# MK65F18 register map
Vendor: NXP Semiconductors; Series: Kinetis_K; File version: 1.6
CPU: CM4 r0p1, little endian, no MPU, FPU, VTOR, 4 interrupt priority bits
Registers are 32-bit, read-write, reset 0x0 unless marked. A register's access mark holds for its fields unless they carry their own. Offsets are from the block's base; [hi:lo] are bit positions; {n}, {i} and the like mark numbered series; 'fields as' and 'values as' point back to an identical list.

## RFSYS — System register file
Base 0x40041000; register names take the prefix RFSYS_
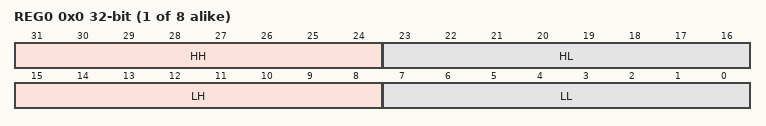
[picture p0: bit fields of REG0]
{0x0+4i} REG{i} (i=0..7) — Register file register
  [31:24] HH — High higher byte
  [23:16] HL — High lower byte
  [15:8] LH — Low higher byte
  [7:0] LL — Low lower byte

## TSI0 — Touch sense input
Base 0x40045000; register names take the prefix TSI0_
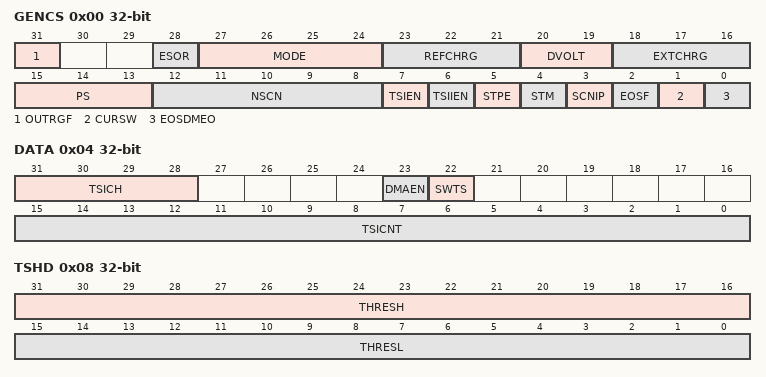
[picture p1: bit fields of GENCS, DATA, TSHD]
0x00 GENCS — TSI General Control and Status Register
  [31] OUTRGF — Out of Range Flag.
  [28] ESOR — End-of-scan or Out-of-Range Interrupt Selection
    0=Out-of-range interrupt is allowed; 1=End-of-scan interrupt is allowed
  [27:24] MODE — TSI analog modes setup and status bits.
    0=Set TSI in capacitive sensing(non-noise detection) mode; 4=Set TSI analog to work in single threshold noise detection mode and the frequency limitation circuit is disabled; 8=Set TSI analog to work in single threshold noise detection mode and the frequency limitation circuit is enabled to work in higher frequencies operations; 12=Set TSI analog to work in automatic noise detection mode
  [23:21] REFCHRG
    0=500 nA; 1=1 uA; 2=2 uA; 3=4 uA; 4=8 uA; 5=16 uA; 6=32 uA; 7=64 uA
  [20:19] DVOLT
    0=DV = 1.026 V; VP = 1.328 V; Vm = 0.302 V; 1=DV = 0.592 V; VP = 1.111 V; Vm = 0.519 V; 2=DV = 0.342 V; VP = 0.986 V; Vm = 0.644 V; 3=DV = 0.197 V; VP = 0.914 V; Vm = 0.716 V
  [18:16] EXTCHRG
    values as REFCHRG
  [15:13] PS
    0=Electrode Oscillator Frequency divided by 1; 1=Electrode Oscillator Frequency divided by 2; 2=Electrode Oscillator Frequency divided by 4; 3=Electrode Oscillator Frequency divided by 8; 4=Electrode Oscillator Frequency divided by 16; 5=Electrode Oscillator Frequency divided by 32; 6=Electrode Oscillator Frequency divided by 64; 7=Electrode Oscillator Frequency divided by 128
  [12:8] NSCN
    0=Once per electrode; 1=Twice per electrode; {v}={v+1} times per electrode (v=2..31)
  [7] TSIEN — Touch Sensing Input Module Enable
    0=TSI module disabled; 1=TSI module enabled
  [6] TSIIEN — Touch Sensing Input Interrupt Enable
    0=TSI interrupt is disabled; 1=TSI interrupt is enabled
  [5] STPE — TSI STOP Enable
    0=TSI is disabled when MCU goes into low power mode; 1=Allows TSI to continue running in all low power modes
  [4] STM — Scan Trigger Mode
    0=Software trigger scan; 1=Hardware trigger scan
  [3] SCNIP ro — Scan In Progress Status
    0=No scan in progress; 1=Scan in progress
  [2] EOSF — End of Scan Flag
    0=Scan not complete; 1=Scan complete
  [1] CURSW
    0=The current source pair are not swapped; 1=The current source pair are swapped
  [0] EOSDMEO — End-of-Scan DMA Transfer Request Enable Only
    0=Do not enable the End-of-Scan DMA transfer request only. Depending on ESOR state, either Out-of-Range or End-of-Scan can trigger a DMA transfer request and interrupt.; 1=Only the End-of-Scan event can trigger a DMA transfer request. The Out-of-Range event only and always triggers an interrupt if TSIIE is set.
0x04 DATA — TSI DATA Register
  [31:28] TSICH
    {v}=Channel {v} (v=0..15)
  [23] DMAEN — DMA Transfer Enabled
    0=Interrupt is selected when the interrupt enable bit is set and the corresponding TSI events assert; 1=DMA transfer request is selected when the interrupt enable bit is set and the corresponding TSI events assert
  [22] SWTS wo — Software Trigger Start
    0=No effect; 1=Start a scan to determine which channel is specified by TSI_DATA[TSICH]
  [15:0] TSICNT ro — TSI Conversion Counter Value
0x08 TSHD — TSI Threshold Register
  [31:16] THRESH — TSI Wakeup Channel High-threshold
  [15:0] THRESL — TSI Wakeup Channel Low-threshold

## EWM — External Watchdog Monitor
Base 0x40061000; register names take the prefix EWM_
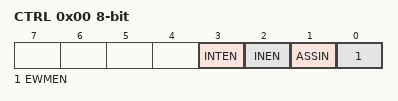
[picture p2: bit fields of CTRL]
0x00 CTRL 8-bit — Control Register
  [3] INTEN — Interrupt Enable.
  [2] INEN — Input Enable.
  [1] ASSIN — EWM_in's Assertion State Select.
  [0] EWMEN — EWM enable.
0x01 SERV 8-bit wo — Service Register
  [7:0] SERVICE — The EWM service mechanism requires the CPU to write two values to the SERV register: a first data byte of 0xB4, followed by a second data byte of 0x2C
0x02 CMPL 8-bit — Compare Low Register
  [7:0] COMPAREL — To prevent runaway code from changing this field, software should write to this field after a CPU reset even if the (default) minimum service time is required
0x03 CMPH 8-bit reset 0xFF — Compare High Register
  [7:0] COMPAREH — To prevent runaway code from changing this field, software should write to this field after a CPU reset even if the (default) maximum service time is required
